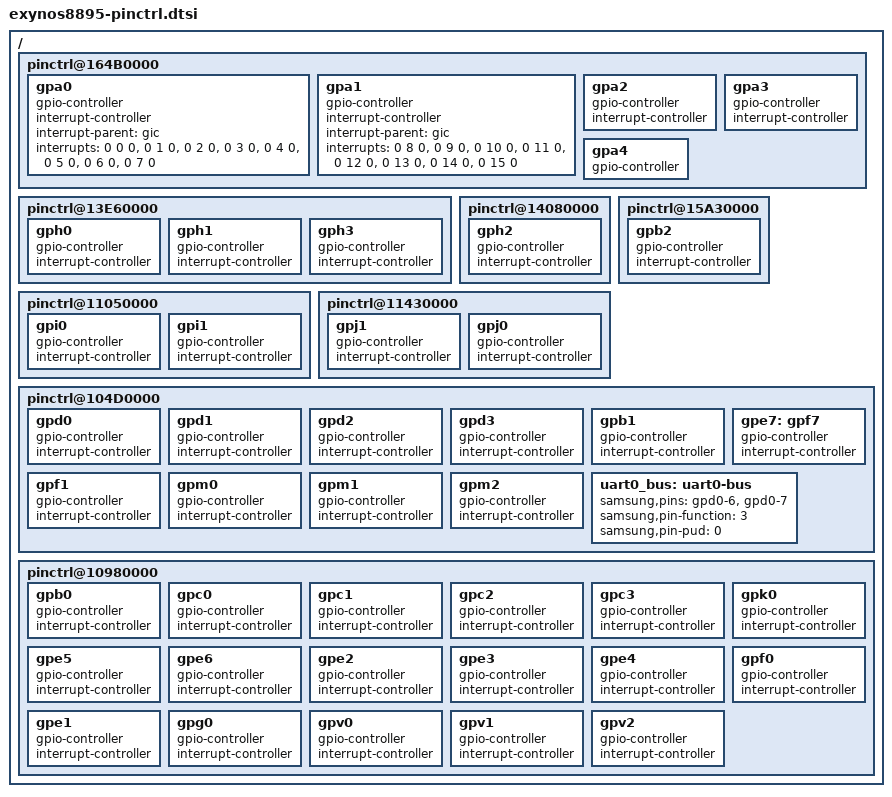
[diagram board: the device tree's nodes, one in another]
/*
 * Samsung's Exynos5430 SoC pin-mux and pin-config device tree source
 *
 * Copyright (c) 2013 Samsung Electronics Co., Ltd.
 *		http://www.samsung.com
 *
 * Samsung's Exynos5430 SoC pin-mux and pin-config options are listed as device
 * tree nodes are listed in this file.
 *
 * This program is free software; you can redistribute it and/or modify
 * it under the terms of the GNU General Public License version 2 as
 * published by the Free Software Foundation.
*/

/ {
	/* ALIVE */
	pinctrl@164B0000 {
		gpa0: gpa0 {
			gpio-controller;
			#gpio-cells = <2>;

			interrupt-controller;
			#interrupt-cells = <2>;
			interrupt-parent = <&gic>;
			interrupts = <0 0 0>, <0 1 0>, <0 2 0>, <0 3 0>,
				     <0 4 0>, <0 5 0>, <0 6 0>, <0 7 0>;
		};

		gpa1: gpa1 {
			gpio-controller;
			#gpio-cells = <2>;

			interrupt-controller;
			#interrupt-cells = <3>;
			interrupt-parent = <&gic>;
			interrupts = <0 8 0>, <0 9 0>, <0 10 0>, <0 11 0>,
				     <0 12 0>, <0 13 0>, <0 14 0>, <0 15 0>;
		};

		gpa2: gpa2 {
			gpio-controller;
			#gpio-cells = <2>;

			interrupt-controller;
			#interrupt-cells = <2>;
		};

		gpa3: gpa3 {
			gpio-controller;
			#gpio-cells = <2>;

			interrupt-controller;
			#interrupt-cells = <2>;
		};

		gpa4: gpa4 {
			gpio-controller;
			#gpio-cells = <2>;
		};

	};

	/* ABOX */
	pinctrl@13E60000 {
		gph0: gph0 {
			gpio-controller;
			#gpio-cells = <2>;

			interrupt-controller;
			#interrupt-cells = <2>;
		};

		gph1: gph1 {
			gpio-controller;
			#gpio-cells = <2>;

			interrupt-controller;
			#interrupt-cells = <2>;
		};

		gph3: gph3 {
			gpio-controller;
			#gpio-cells = <2>;

			interrupt-controller;
			#interrupt-cells = <2>;
		};

	};

	/* VTS */
	pinctrl@14080000 {
		gph2: gph2 {
			gpio-controller;
			#gpio-cells = <2>;

			interrupt-controller;
			#interrupt-cells = <2>;
		};
	};

	/* FSYS0 */
	pinctrl@11050000 {
		gpi0: gpi0 {
			gpio-controller;
			#gpio-cells = <2>;

			interrupt-controller;
			#interrupt-cells = <2>;
		};
		gpi1: gpi1 {
			gpio-controller;
			#gpio-cells = <2>;

			interrupt-controller;
			#interrupt-cells = <2>;
		};
	};

	/* FSYS1 */
	pinctrl@11430000 {
		gpj1: gpj1 {
			gpio-controller;
			#gpio-cells = <2>;

			interrupt-controller;
			#interrupt-cells = <2>;
		};
		gpj0: gpj0 {
			gpio-controller;
			#gpio-cells = <2>;

			interrupt-controller;
			#interrupt-cells = <2>;
		};
	};

	/* BUSC */
	pinctrl@15A30000 {
		gpb2: gpb2 {
			gpio-controller;
			#gpio-cells = <2>;

			interrupt-controller;
			#interrupt-cells = <2>;
		};
	};

	/* PERIC0 */
	pinctrl@104D0000 {
		gpd0: gpd0 {
			gpio-controller;
			#gpio-cells = <2>;

			interrupt-controller;
			#interrupt-cells = <2>;
		};

		gpd1: gpd1 {
			gpio-controller;
			#gpio-cells = <2>;

			interrupt-controller;
			#interrupt-cells = <2>;
		};

		gpd2: gpd2 {
			gpio-controller;
			#gpio-cells = <2>;

			interrupt-controller;
			#interrupt-cells = <2>;
		};

		gpd3: gpd3 {
			gpio-controller;
			#gpio-cells = <2>;

			interrupt-controller;
			#interrupt-cells = <2>;
		};

		gpb1: gpb1 {
			gpio-controller;
			#gpio-cells = <2>;

			interrupt-controller;
			#interrupt-cells = <2>;
		};

		gpe7: gpf7 {
			gpio-controller;
			#gpio-cells = <2>;

			interrupt-controller;
			#interrupt-cells = <2>;
		};

		gpf1: gpf1 {
			gpio-controller;
			#gpio-cells = <2>;

			interrupt-controller;
			#interrupt-cells = <2>;
		};

		gpm0: gpm0 {
			gpio-controller;
			#gpio-cells = <2>;

			interrupt-controller;
			#interrupt-cells = <2>;
		};

		gpm1: gpm1 {
			gpio-controller;
			#gpio-cells = <2>;

			interrupt-controller;
			#interrupt-cells = <2>;
		};

		gpm2: gpm2 {
			gpio-controller;
			#gpio-cells = <2>;

			interrupt-controller;
			#interrupt-cells = <2>;
		};

		uart0_bus: uart0-bus {
			samsung,pins = "gpd0-6", "gpd0-7";
			samsung,pin-function = <3>;
			samsung,pin-pud = <0>;
		};
	};

	/* PERIC1 */
	pinctrl@10980000 {
		gpb0: gpb0 {
			gpio-controller;
			#gpio-cells = <2>;

			interrupt-controller;
			#interrupt-cells = <2>;
		};

		gpc0: gpc0 {
			gpio-controller;
			#gpio-cells = <2>;

			interrupt-controller;
			#interrupt-cells = <2>;
		};

		gpc1: gpc1 {
			gpio-controller;
			#gpio-cells = <2>;

			interrupt-controller;
			#interrupt-cells = <2>;
		};

		gpc2: gpc2 {
			gpio-controller;
			#gpio-cells = <2>;

			interrupt-controller;
			#interrupt-cells = <2>;
		};

		gpc3: gpc3 {
			gpio-controller;
			#gpio-cells = <2>;

			interrupt-controller;
			#interrupt-cells = <2>;
		};

		gpk0: gpk0 {
			gpio-controller;
			#gpio-cells = <2>;

			interrupt-controller;
			#interrupt-cells = <2>;
		};

		gpe5: gpe5 {
			gpio-controller;
			#gpio-cells = <2>;

			interrupt-controller;
			#interrupt-cells = <2>;
		};

		gpe6: gpe6 {
			gpio-controller;
			#gpio-cells = <2>;

			interrupt-controller;
			#interrupt-cells = <2>;
		};

		gpe2: gpe2 {
			gpio-controller;
			#gpio-cells = <2>;

			interrupt-controller;
			#interrupt-cells = <2>;
		};

		gpe3: gpe3 {
			gpio-controller;
			#gpio-cells = <2>;

			interrupt-controller;
			#interrupt-cells = <2>;
		};

		gpe4: gpe4 {
			gpio-controller;
			#gpio-cells = <2>;

			interrupt-controller;
			#interrupt-cells = <2>;
		};

		gpf0: gpf0 {
			gpio-controller;
			#gpio-cells = <2>;

			interrupt-controller;
			#interrupt-cells = <2>;
		};

		gpe1: gpe1 {
			gpio-controller;
			#gpio-cells = <2>;

			interrupt-controller;
			#interrupt-cells = <2>;
		};

		gpg0: gpg0 {
			gpio-controller;
			#gpio-cells = <2>;

			interrupt-controller;
			#interrupt-cells = <2>;
		};

		gpv0: gpv0 {
			gpio-controller;
			#gpio-cells = <2>;

			interrupt-controller;
			#interrupt-cells = <2>;
		};

		gpv1: gpv1 {
			gpio-controller;
			#gpio-cells = <2>;

			interrupt-controller;
			#interrupt-cells = <2>;
		};

		gpv2: gpv2 {
			gpio-controller;
			#gpio-cells = <2>;

			interrupt-controller;
			#interrupt-cells = <2>;
		};
	};
};

